# CS__Clock_System_1 register map
Vendor: Texas Instruments
Peripheral module from a debugger description file (folder msp430).
Registers are 16-bit, read-write, reset 0x0 unless marked. A register's access mark holds for its fields unless they carry their own. Offsets are as the file gives them; lines under a group give offsets from that group; [hi:lo] are bit positions; {n}, {i} and the like mark numbered series; 'fields as' and 'values as' point back to an identical list; <NAME> marks a mode.

## CS_Clock_System
0x160 CSCTL0 access not given reset not defined — CS Control Register 0
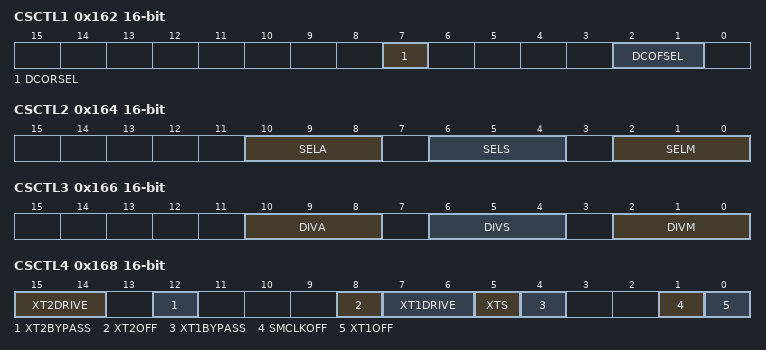
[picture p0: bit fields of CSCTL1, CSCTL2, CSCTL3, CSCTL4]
0x162 CSCTL1 — CS Control Register 1
  [7] DCORSEL — DCO range select.
  [2:1] DCOFSEL — DCO frequency select Bit: 0
    {v}=DCO frequency select: {v} (v=0..3)
0x164 CSCTL2 — CS Control Register 2
  [10:8] SELA — ACLK Source Select Bit: 0
    {v}=ACLK Source Select {v} (v=0..7)
  [6:4] SELS — SMCLK Source Select Bit: 0
    {v}=SMCLK Source Select {v} (v=0..7)
  [2:0] SELM — MCLK Source Select Bit: 0
    {v}=MCLK Source Select {v} (v=0..7)
0x166 CSCTL3 — CS Control Register 3
  [10:8] DIVA — ACLK Divider Bit: 0
    {v}=ACLK Source Divider {v} (v=0..5)
  [6:4] DIVS — SMCLK Divider Bit: 0
    {v}=SMCLK Source Divider {v} (v=0..5)
  [2:0] DIVM — MCLK Divider Bit: 0
    {v}=MCLK Source Divider {v} (v=0..5)
0x168 CSCTL4 — CS Control Register 4
  [15:14] XT2DRIVE — XT2 Drive Level mode Bit 0
    {v}=XT2 Drive Level mode: {v} (v=0..3)
  [12] XT2BYPASS — XT2 bypass mode : 0: internal 1:sourced from external pin
  [8] XT2OFF — High Frequency Oscillator 2 (XT2) disable
  [7:6] XT1DRIVE — XT1 Drive Level mode Bit 0
    {v}=XT1 Drive Level mode: {v} (v=0..3)
  [5] XTS — 1: Selects high-freq. oscillator
  [4] XT1BYPASS — XT1 bypass mode : 0: internal 1:sourced from external pin
  [1] SMCLKOFF
  [0] XT1OFF — High Frequency Oscillator 1 (XT1) disable
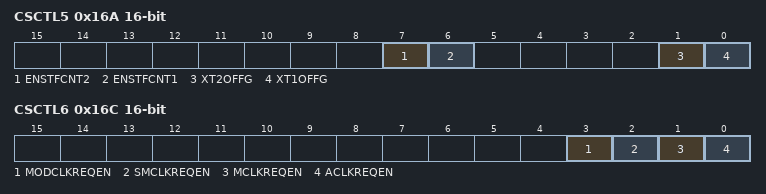
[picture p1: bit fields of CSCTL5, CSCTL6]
0x16A CSCTL5 — CS Control Register 5
  [7] ENSTFCNT2 — Enable start counter for XT2
  [6] ENSTFCNT1 — Enable start counter for XT1
  [1] XT2OFFG — High Frequency Oscillator 2 Fault Flag
  [0] XT1OFFG — XT1 Low Frequency Oscillator Fault Flag
0x16C CSCTL6 — CS Control Register 6
  [3] MODCLKREQEN — MODOSC Clock Request Enable
  [2] SMCLKREQEN — SMCLK Clock Request Enable
  [1] MCLKREQEN — MCLK Clock Request Enable
  [0] ACLKREQEN — ACLK Clock Request Enable
